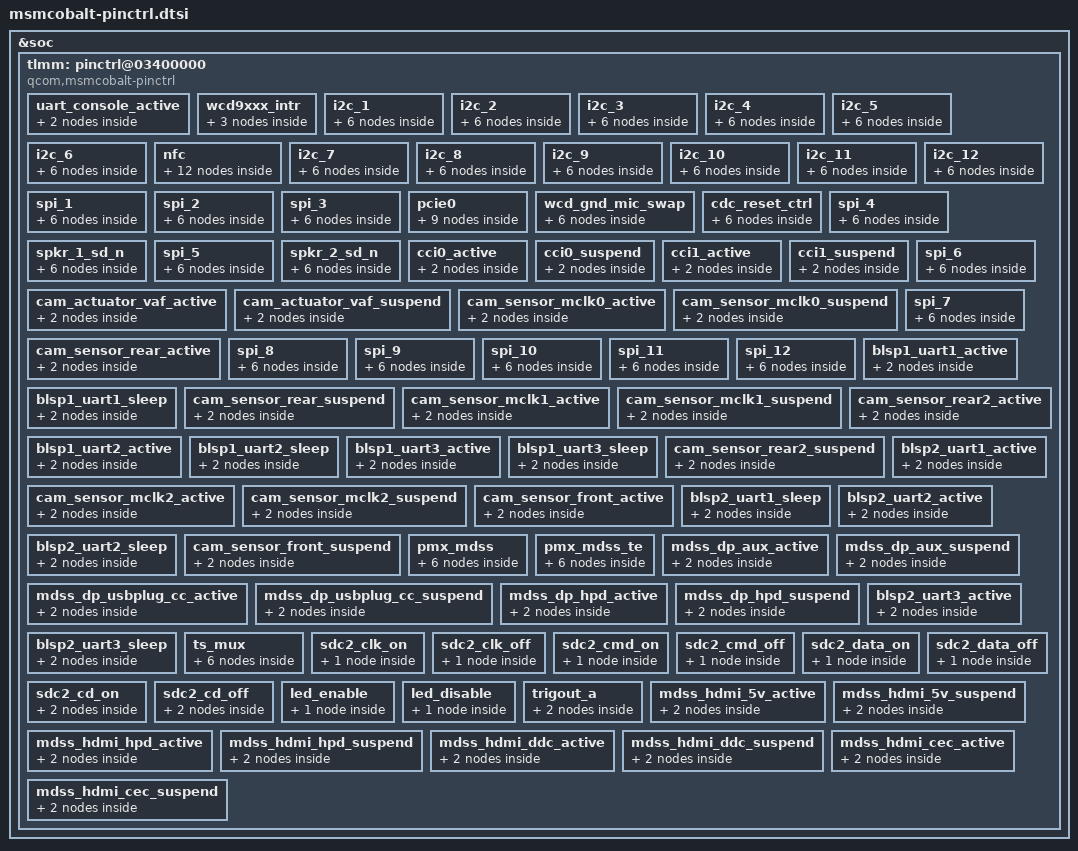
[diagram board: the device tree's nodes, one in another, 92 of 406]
/* Copyright (c) 2015-2016, The Linux Foundation. All rights reserved.
 *
 * This program is free software; you can redistribute it and/or modify
 * it under the terms of the GNU General Public License version 2 and
 * only version 2 as published by the Free Software Foundation.
 *
 * This program is distributed in the hope that it will be useful,
 * but WITHOUT ANY WARRANTY; without even the implied warranty of
 * MERCHANTABILITY or FITNESS FOR A PARTICULAR PURPOSE.  See the
 * GNU General Public License for more details.
 */

&soc {
	tlmm: pinctrl@03400000 {
		compatible = "qcom,msmcobalt-pinctrl";
		reg = <0x03400000 0xc00000>;
		interrupts = <0 208 0>;
		gpio-controller;
		#gpio-cells = <2>;
		interrupt-controller;
		#interrupt-cells = <2>;

		uart_console_active: uart_console_active {
			mux {
				pins = "gpio4", "gpio5";
				function = "blsp_uart8_a";
			};

			config {
				pins = "gpio4", "gpio5";
				drive-strength = <2>;
				bias-disable;
			};
		};

		wcd9xxx_intr {
			wcd_intr_default: wcd_intr_default{
				mux {
					pins = "gpio54";
					function = "gpio";
				};

				config {
					pins = "gpio54";
					drive-strength = <2>; /* 2 mA */
					bias-pull-down; /* pull down */
					input-enable;
				};
			};
		};

		/* I2C CONFIGURATION */
		i2c_1 {
			i2c_1_active: i2c_1_active {
				mux {
					pins = "gpio2", "gpio3";
					function = "blsp_i2c1";
				};

				config {
					pins = "gpio2", "gpio3";
					drive-strength = <2>;
					bias-disable;
				};
			};

			i2c_1_sleep: i2c_1_sleep {
				mux {
					pins = "gpio2", "gpio3";
					function = "blsp_i2c1";
				};

				config {
					pins = "gpio2", "gpio3";
					drive-strength = <2>;
					bias-pull-up;
				};
			};
		};

		i2c_2 {
			i2c_2_active: i2c_2_active {
				mux {
					pins = "gpio32", "gpio33";
					function = "blsp_i2c2";
				};

				config {
					pins = "gpio32", "gpio33";
					drive-strength = <2>;
					bias-disable;
				};
			};

			i2c_2_sleep: i2c_2_sleep {
				mux {
					pins = "gpio32", "gpio33";
					function = "blsp_i2c2";
				};

				config {
					pins = "gpio32", "gpio33";
					drive-strength = <2>;
					bias-pull-up;
				};
			};
		};

		i2c_3 {
			i2c_3_active: i2c_3_active {
				mux {
					pins = "gpio47", "gpio48";
					function = "blsp_i2c3";
				};

				config {
					pins = "gpio47", "gpio48";
					drive-strength = <2>;
					bias-disable;
				};
			};

			i2c_3_sleep: i2c_3_sleep {
				mux {
					pins = "gpio47", "gpio48";
					function = "blsp_i2c3";
				};

				config {
					pins = "gpio47", "gpio48";
					drive-strength = <2>;
					bias-pull-up;
				};
			};
		};

		i2c_4 {
			i2c_4_active: i2c_4_active {
				mux {
					pins = "gpio10", "gpio11";
					function = "blsp_i2c4";
				};

				config {
					pins = "gpio10", "gpio11";
					drive-strength = <2>;
					bias-disable;
				};
			};

			i2c_4_sleep: i2c_4_sleep {
				mux {
					pins = "gpio10", "gpio11";
					function = "blsp_i2c4";
				};

				config {
					pins = "gpio10", "gpio11";
					drive-strength = <2>;
					bias-pull-up;
				};
			};
		};

		i2c_5 {
			i2c_5_active: i2c_5_active {
				mux {
					pins = "gpio87", "gpio88";
					function = "blsp_i2c5";
				};

				config {
					pins = "gpio87", "gpio88";
					drive-strength = <2>;
					bias-disable;
				};
			};

			i2c_5_sleep: i2c_5_sleep {
				mux {
					pins = "gpio87", "gpio88";
					function = "blsp_i2c5";
				};

				config {
					pins = "gpio87", "gpio88";
					drive-strength = <2>;
					bias-pull-up;
				};
			};
		};

		i2c_6 {
			i2c_6_active: i2c_6_active {
				mux {
					pins = "gpio43", "gpio44";
					function = "blsp_i2c6";
				};

				config {
					pins = "gpio43", "gpio44";
					drive-strength = <2>;
					bias-disable;
				};
			};

			i2c_6_sleep: i2c_6_sleep {
				mux {
					pins = "gpio43", "gpio44";
					function = "blsp_i2c6";
				};

				config {
					pins = "gpio43", "gpio44";
					drive-strength = <2>;
					bias-pull-up;
				};
			};
		};

		nfc {
			nfc_int_active: nfc_int_active {
				/* active state */
				mux {
					/* GPIO 92 NFC Read Interrupt */
					pins = "gpio92";
					function = "gpio";
				};

				config {
					pins = "gpio92";
					drive-strength = <6>; /* 6 MA */
					bias-pull-up;
				};
			};

			nfc_int_suspend: nfc_int_suspend {
				/* sleep state */
				mux {
					/* GPIO 92 NFC Read Interrupt */
					pins = "gpio92";
					function = "gpio";
				};

				config {
					pins = "gpio92";
					drive-strength = <6>; /* 6 MA */
					bias-pull-up;
				};
			};

			nfc_enable_active: nfc_enable_active {
				/* active state */
				mux {
					/* 12: NFC ENABLE 116:ESE Enable */
					pins = "gpio12", "gpio116";
					function = "gpio";
				};

				config {
					pins = "gpio12", "gpio116";
					drive-strength = <6>; /* 6 MA */
					bias-pull-up;
				};
			};

			nfc_enable_suspend: nfc_enable_suspend {
				/* sleep state */
				mux {
					/* 12: NFC ENABLE 116:ESE Enable */
					pins = "gpio12", "gpio116";
					function = "gpio";
				};

				config {
					pins = "gpio12", "gpio116";
					drive-strength = <6>; /* 6 MA */
					bias-disable;
				};
			};
		};

		i2c_7 {
			i2c_7_active: i2c_7_active {
				mux {
					pins = "gpio55", "gpio56";
					function = "blsp_i2c7";
				};

				config {
					pins = "gpio55", "gpio56";
					drive-strength = <2>;
					bias-disable;
				};
			};

			i2c_7_sleep: i2c_7_sleep {
				mux {
					pins = "gpio55", "gpio56";
					function = "blsp_i2c7";
				};

				config {
					pins = "gpio55", "gpio56";
					drive-strength = <2>;
					bias-pull-up;
				};
			};
		};

		i2c_8 {
			i2c_8_active: i2c_8_active {
				mux {
					pins = "gpio6", "gpio7";
					function = "blsp_i2c8";
				};

				config {
					pins = "gpio6", "gpio7";
					drive-strength = <2>;
					bias-disable;
				};
			};

			i2c_8_sleep: i2c_8_sleep {
				mux {
					pins = "gpio6", "gpio7";
					function = "blsp_i2c8";
				};

				config {
					pins = "gpio6", "gpio7";
					drive-strength = <2>;
					bias-pull-up;
				};
			};
		};

		i2c_9 {
			i2c_9_active: i2c_9_active {
				mux {
					pins = "gpio51", "gpio52";
					function = "blsp_i2c9";
				};

				config {
					pins = "gpio51", "gpio52";
					drive-strength = <2>;
					bias-disable;
				};
			};

			i2c_9_sleep: i2c_9_sleep {
				mux {
					pins = "gpio51", "gpio52";
					function = "blsp_i2c9";
				};

				config {
					pins = "gpio51", "gpio52";
					drive-strength = <2>;
					bias-pull-up;
				};
			};
		};

		i2c_10 {
			i2c_10_active: i2c_10_active {
				mux {
					pins = "gpio67", "gpio68";
					function = "blsp_i2c10";
				};

				config {
					pins = "gpio67", "gpio68";
					drive-strength = <2>;
					bias-disable;
				};
			};

			i2c_10_sleep: i2c_10_sleep {
				mux {
					pins = "gpio67", "gpio68";
					function = "blsp_i2c10";
				};

				config {
					pins = "gpio67", "gpio68";
					drive-strength = <2>;
					bias-pull-up;
				};
			};
		};

		i2c_11 {
			i2c_11_active: i2c_11_active {
				mux {
					pins = "gpio60", "gpio61";
					function = "blsp_i2c11";
				};

				config {
					pins = "gpio60", "gpio61";
					drive-strength = <2>;
					bias-disable;
				};
			};

			i2c_11_sleep: i2c_11_sleep {
				mux {
					pins = "gpio60", "gpio61";
					function = "blsp_i2c11";
				};

				config {
					pins = "gpio60", "gpio61";
					drive-strength = <2>;
					bias-pull-up;
				};
			};
		};

		i2c_12 {
			i2c_12_active: i2c_12_active {
				mux {
					pins = "gpio83", "gpio84";
					function = "blsp_i2c12";
				};

				config {
					pins = "gpio83", "gpio84";
					drive-strength = <2>;
					bias-disable;
				};
			};

			i2c_12_sleep: i2c_12_sleep {
				mux {
					pins = "gpio83", "gpio84";
					function = "blsp_i2c12";
				};

				config {
					pins = "gpio83", "gpio84";
					drive-strength = <2>;
					bias-pull-up;
				};
			};
		};

		/* SPI CONFIGURATION */

		spi_1 {
			spi_1_active: spi_1_active {
				mux {
					pins = "gpio0", "gpio1",
							"gpio2", "gpio3";
					function = "blsp_spi1";
				};

				config {
					pins = "gpio0", "gpio1",
							"gpio2", "gpio3";
					drive-strength = <6>;
					bias-disable;
				};
			};

			spi_1_sleep: spi_1_sleep {
				mux {
					pins = "gpio0", "gpio1",
							"gpio2", "gpio3";
					function = "blsp_spi1";
				};

				config {
					pins = "gpio0", "gpio1",
							"gpio2", "gpio3";
					drive-strength = <6>;
					bias-disable;
				};
			};
		};

		spi_2 {
			spi_2_active: spi_2_active {
				mux {
					pins = "gpio31", "gpio34",
							"gpio32", "gpio33";
					function = "blsp_spi2";
				};

				config {
					pins = "gpio31", "gpio34",
							"gpio32", "gpio33";
					drive-strength = <6>;
					bias-disable;
				};
			};

			spi_2_sleep: spi_2_sleep {
				mux {
					pins = "gpio31", "gpio34",
							"gpio32", "gpio33";
					function = "blsp_spi2";
				};

				config {
					pins = "gpio31", "gpio34",
							"gpio32", "gpio33";
					drive-strength = <6>;
					bias-disable;
				};
			};
		};

		spi_3 {
			spi_3_active: spi_3_active {
				mux {
					pins = "gpio45", "gpio46",
							"gpio47", "gpio48";
					function = "blsp_spi3";
				};

				config {
					pins = "gpio45", "gpio46",
							"gpio47", "gpio48";
					drive-strength = <6>;
					bias-disable;
				};
			};

			spi_3_sleep: spi_3_sleep {
				mux {
					pins = "gpio45", "gpio46",
							"gpio47", "gpio48";
					function = "blsp_spi3";
				};

				config {
					pins = "gpio45", "gpio46",
							"gpio47", "gpio48";
					drive-strength = <6>;
					bias-disable;
				};
			};
		};

		pcie0 {
			pcie0_clkreq_default: pcie0_clkreq_default {
				mux {
					pins = "gpio36";
					function = "pci_e0";
				};

				config {
					pins = "gpio36";
					drive-strength = <2>;
					bias-pull-up;
				};
			};

			pcie0_perst_default: pcie0_perst_default {
				mux {
					pins = "gpio35";
					function = "gpio";
				};

				config {
					pins = "gpio35";
					drive-strength = <2>;
					bias-pull-down;
				};
			};

			pcie0_wake_default: pcie0_wake_default {
				mux {
					pins = "gpio37";
					function = "gpio";
				};

				config {
					pins = "gpio37";
					drive-strength = <2>;
					bias-pull-down;
				};
			};
		};

		wcd_gnd_mic_swap {
			wcd_gnd_mic_swap_idle: wcd_gnd_mic_swap_idle {
				mux {
					pins = "gpio75";
					function = "gpio";
				};
				config {
					pins = "gpio75";
					drive-strength = <2>;
					bias-pull-down;
					output-low;
				};
			};
			wcd_gnd_mic_swap_active: wcd_gnd_mic_swap_active {
				mux {
					pins = "gpio75";
					function = "gpio";
				};
				config {
					pins = "gpio75";
					drive-strength = <2>;
					bias-disable;
					output-high;
				};
			};
		};


		cdc_reset_ctrl {
			cdc_reset_sleep: cdc_reset_sleep {
				mux {
					pins = "gpio64";
					function = "gpio";
				};
				config {
					pins = "gpio64";
					drive-strength = <16>;
					bias-disable;
					output-low;
				};
			};
			cdc_reset_active:cdc_reset_active {
				mux {
					pins = "gpio64";
					function = "gpio";
				};
				config {
					pins = "gpio64";
					drive-strength = <16>;
					bias-pull-down;
					output-high;
				};
			};
		};

		spi_4 {
			spi_4_active: spi_4_active {
				mux {
					pins = "gpio8", "gpio9",
							"gpio10", "gpio1";
					function = "blsp_spi4";
				};

				config {
					pins = "gpio8", "gpio9",
							"gpio10", "gpio1";
					drive-strength = <6>;
					bias-disable;
				};
			};

			spi_4_sleep: spi_4_sleep {
				mux {
					pins = "gpio8", "gpio9",
							"gpio10", "gpio1";
					function = "blsp_spi4";
				};

				config {
					pins = "gpio8", "gpio9",
							"gpio10", "gpio1";
					drive-strength = <6>;
					bias-disable;
				};
			};
		};

		spkr_1_sd_n {
			spkr_1_sd_n_sleep: spkr_1_sd_n_sleep {
				mux {
					pins = "gpio65";
					function = "gpio";
				};
				config {
					pins = "gpio65";
					drive-strength = <2>;   /* 2 mA */
					bias-pull-down;
					input-enable;
				};
			};
			spkr_1_sd_n_active: spkr_1_sd_n_active {
				mux {
					pins = "gpio65";
					function = "gpio";
				};
				config {
					pins = "gpio65";
					drive-strength = <16>;   /* 16 mA */
					bias-disable;
					output-high;
				};
			};
		};

		spi_5 {
			spi_5_active: spi_5_active {
				mux {
					pins = "gpio0", "gpio",
							"gpio2", "gpio3";
					function = "blsp_spi5";
				};

				config {
					pins = "gpio85", "gpio86",
							"gpio87", "gpio88";
					drive-strength = <6>;
					bias-disable;
				};
			};

			spi_5_sleep: spi_5_sleep {
				mux {
					pins = "gpio85", "gpio86",
							"gpio87", "gpio88";
					function = "blsp_spi5";
				};

				config {
					pins = "gpio85", "gpio86",
							"gpio87", "gpio88";
					drive-strength = <6>;
					bias-disable;
				};
			};
		};

		spkr_2_sd_n {
			spkr_2_sd_n_sleep: spkr_2_sd_n_sleep {
				mux {
					pins = "gpio66";
					function = "gpio";
				};
				config {
					pins = "gpio66";
					drive-strength = <2>;   /* 2 mA */
					bias-pull-down;
					input-enable;
				};
			};
			spkr_2_sd_n_active: spkr_2_sd_n_active {
				mux {
					pins = "gpio66";
					function = "gpio";
				};
				config {
					pins = "gpio66";
					drive-strength = <16>;   /* 16 mA */
					bias-disable;
					output-high;
				};
			};
		};

		cci0_active: cci0_active {
			mux {
				/* CLK, DATA */
				pins = "gpio17","gpio18"; // Only 2
				function = "cci_i2c";
			};

			config {
				pins = "gpio17","gpio18";
				bias-pull-up; /* PULL UP*/
				drive-strength = <2>; /* 2 MA */
			};
		};

		cci0_suspend: cci0_suspend {
			mux {
				/* CLK, DATA */
				pins = "gpio17","gpio18";
				function = "cci_i2c";
			};

			config {
				pins = "gpio17","gpio18";
				bias-pull-down; /* PULL DOWN */
				drive-strength = <2>; /* 2 MA */
			};
		};

		cci1_active: cci1_active {
			mux {
				/* CLK, DATA */
				pins = "gpio19","gpio20";
				function = "cci_i2c";
			};

			config {
				pins = "gpio19","gpio20";
				bias-pull-up; /* PULL UP*/
				drive-strength = <2>; /* 2 MA */
			};
		};

		cci1_suspend: cci1_suspend {
			mux {
				/* CLK, DATA */
				pins = "gpio19","gpio20";
				function = "cci_i2c";
			};

			config {
				pins = "gpio19","gpio20";
				bias-pull-down; /* PULL DOWN */
				drive-strength = <2>; /* 2 MA */
			};
		};

		cam_actuator_vaf_active: cam_actuator_vaf_active {
			/* ACTUATOR POWER */
			mux {
				pins = "gpio27";
				function = "gpio";
			};

			config {
				pins = "gpio27";
				bias-disable; /* No PULL */
				drive-strength = <2>; /* 2 MA */
			};
		};

		cam_actuator_vaf_suspend: cam_actuator_vaf_suspend {
			/* ACTUATOR POWER */
			mux {
				pins = "gpio27";
				function = "gpio";
			};

			config {
				pins = "gpio27";
				bias-pull-down; /* PULL DOWN */
				drive-strength = <2>; /* 2 MA */
			};
		};

		cam_sensor_mclk0_active: cam_sensor_mclk0_active {
			/* MCLK0 */
			mux {
				/* CLK, DATA */
				pins = "gpio13";
				function = "cam_mclk";
			};

			config {
				pins = "gpio13";
				bias-disable; /* No PULL */
				drive-strength = <2>; /* 2 MA */
			};
		};

		cam_sensor_mclk0_suspend: cam_sensor_mclk0_suspend {
			/* MCLK0 */
			mux {
				/* CLK, DATA */
				pins = "gpio13";
				function = "cam_mclk";
			};

			config {
				pins = "gpio13";
				bias-pull-down; /* PULL DOWN */
				drive-strength = <2>; /* 2 MA */
			};
		};

		cam_sensor_rear_active: cam_sensor_rear_active {
			/* RESET, STANDBY */
			mux {
				pins = "gpio30","gpio29";
				function = "gpio";
			};

			config {
				pins = "gpio30","gpio29";
				bias-disable; /* No PULL */
				drive-strength = <2>; /* 2 MA */
			};
		};

		spi_6 {
			spi_6_active: spi_6_active {
				mux {
					pins = "gpio41", "gpio42",
							"gpio43", "gpio44";
					function = "blsp_spi6";
				};

				config {
					pins = "gpio41", "gpio42",
							"gpio43", "gpio44";
					drive-strength = <6>;
					bias-disable;
				};
			};

			spi_6_sleep: spi_6_sleep {
				mux {
					pins = "gpio41", "gpio42",
							"gpio43", "gpio44";
					function = "blsp_spi6";
				};

				config {
					pins = "gpio41", "gpio42",
							"gpio43", "gpio44";
					drive-strength = <6>;
					bias-disable;
				};
			};
		};

		spi_7 {
			spi_7_active: spi_7_active {
				mux {
					pins = "gpio53", "gpio54",
							"gpio55", "gpio56";
					function = "blsp_spi7";
				};

				config {
					pins = "gpio53", "gpio54",
							"gpio55", "gpio56";
					drive-strength = <6>;
					bias-disable;
				};
			};

			spi_7_sleep: spi_7_sleep {
				mux {
					pins = "gpio53", "gpio54",
							"gpio55", "gpio56";
					function = "blsp_spi7";
				};

				config {
					pins = "gpio53", "gpio54",
							"gpio55", "gpio56";
					drive-strength = <6>;
					bias-disable;
				};
			};
		};

		spi_8 {
			spi_8_active: spi_8_active {
				mux {
					pins = "gpio4", "gpio5",
							"gpio6", "gpio7";
					function = "blsp_spi8";
				};

				config {
					pins = "gpio4", "gpio5",
							"gpio6", "gpio7";
					drive-strength = <6>;
					bias-disable;
				};
			};

			spi_8_sleep: spi_8_sleep {
				mux {
					pins = "gpio4", "gpio5",
							"gpio6", "gpio7";
					function = "blsp_spi8";
				};

				config {
					pins = "gpio4", "gpio5",
							"gpio6", "gpio7";
					drive-strength = <6>;
					bias-disable;
				};
			};
		};

		spi_9 {
			spi_9_active: spi_9_active {
				mux {
					pins = "gpio49", "gpio50",
							"gpio51", "gpio52";
					function = "blsp_spi9";
				};

				config {
					pins = "gpio49", "gpio50",
							"gpio51", "gpio52";
					drive-strength = <6>;
					bias-disable;
				};
			};

			spi_9_sleep: spi_9_sleep {
				mux {
					pins = "gpio49", "gpio50",
							"gpio51", "gpio52";
					function = "blsp_spi9";
				};

				config {
					pins = "gpio49", "gpio50",
							"gpio51", "gpio52";
					drive-strength = <6>;
					bias-disable;
				};
			};
		};

		spi_10 {
			spi_10_active: spi_10_active {
				mux {
					pins = "gpio65", "gpio66",
							"gpio67", "gpio68";
					function = "blsp_spi10";
				};

				config {
					pins = "gpio65", "gpio66",
							"gpio67", "gpio68";
					drive-strength = <6>;
					bias-disable;
				};
			};

			spi_10_sleep: spi_10_sleep {
				mux {
					pins = "gpio65", "gpio66",
							"gpio67", "gpio68";
					function = "blsp_spi10";
				};

				config {
					pins = "gpio65", "gpio66",
							"gpio67", "gpio68";
					drive-strength = <6>;
					bias-disable;
				};
			};
		};

		spi_11 {
			spi_11_active: spi_11_active {
				mux {
					pins = "gpio58", "gpio59",
							"gpio60", "gpio61";
					function = "blsp_spi11";
				};

				config {
					pins = "gpio58", "gpio59",
							"gpio60", "gpio61";
					drive-strength = <6>;
					bias-disable;
				};
			};

			spi_11_sleep: spi_11_sleep {
				mux {
					pins = "gpio58", "gpio59",
							"gpio60", "gpio61";
					function = "blsp_spi11";
				};

				config {
					pins = "gpio58", "gpio59",
							"gpio60", "gpio61";
					drive-strength = <6>;
					bias-disable;
				};
			};
		};

		spi_12 {
			spi_12_active: spi_12_active {
				mux {
					pins = "gpio81", "gpio82",
							"gpio83", "gpio84";
					function = "blsp_spi12";
				};

				config {
					pins = "gpio81", "gpio82",
							"gpio83", "gpio84";
					drive-strength = <6>;
					bias-disable;
				};
			};

			spi_12_sleep: spi_12_sleep {
				mux {
					pins = "gpio81", "gpio82",
							"gpio83", "gpio84";
					function = "blsp_spi12";
				};

				config {
					pins = "gpio81", "gpio82",
							"gpio83", "gpio84";
					drive-strength = <6>;
					bias-disable;
				};
			};
		};

		/* HS UART CONFIGURATION */
		blsp1_uart1_active: blsp1_uart1_active {
			mux {
				pins = "gpio0", "gpio1", "gpio2", "gpio3";
				function = "blsp_uart1_a";
			};

			config {
				pins = "gpio0", "gpio1", "gpio2", "gpio3";
				drive-strength = <2>;
				bias-disable;
			};
		};

		blsp1_uart1_sleep: blsp1_uart1_sleep {
			mux {
				pins = "gpio0", "gpio1", "gpio2", "gpio3";
				function = "gpio";
			};

			config {
				pins = "gpio0", "gpio1", "gpio2", "gpio3";
				drive-strength = <2>;
				bias-disable;
			};
		};

		cam_sensor_rear_suspend: cam_sensor_rear_suspend {
			/* RESET, STANDBY */
			mux {
				pins = "gpio30","gpio29";
				function = "gpio";
			};

			config {
				pins = "gpio30","gpio29";
				bias-disable; /* No PULL */
				drive-strength = <2>; /* 2 MA */
			};
		};

		cam_sensor_mclk1_active: cam_sensor_mclk1_active {
			/* MCLK1 */
			mux {
				/* CLK, DATA */
				pins = "gpio14";
				function = "cam_mclk";
			};

			config {
				pins = "gpio14";
				bias-disable; /* No PULL */
				drive-strength = <2>; /* 2 MA */
			};
		};

		cam_sensor_mclk1_suspend: cam_sensor_mclk1_suspend {
			/* MCLK1 */
			mux {
				/* CLK, DATA */
				pins = "gpio14";
				function = "cam_mclk";
			};

			config {
				pins = "gpio14";
				bias-pull-down; /* PULL DOWN */
				drive-strength = <2>; /* 2 MA */
			};
		};

		cam_sensor_rear2_active: cam_sensor_rear2_active {
			/* RESET, STANDBY */
			mux {
				pins = "gpio9","gpio8";
				function = "gpio";
			};

			config {
				pins = "gpio9","gpio8";
				bias-disable; /* No PULL */
				drive-strength = <2>; /* 2 MA */
			};
		};

		blsp1_uart2_active: blsp1_uart2_active {
			mux {
				pins = "gpio31", "gpio34", "gpio33", "gpio32";
				function = "blsp_uart2_a";
			};

			config {
				pins = "gpio31", "gpio34", "gpio33", "gpio32";
				drive-strength = <2>;
				bias-disable;
			};
		};

		blsp1_uart2_sleep: blsp1_uart2_sleep {
			mux {
				pins = "gpio31", "gpio34", "gpio33", "gpio32";
				function = "gpio";
			};

			config {
				pins = "gpio31", "gpio34", "gpio33", "gpio32";
				drive-strength = <2>;
				bias-disable;
			};
		};

		blsp1_uart3_active: blsp1_uart3_active {
			mux {
				pins = "gpio45", "gpio46", "gpio47", "gpio48";
				function = "blsp_uart3_a";
			};

			config {
				pins = "gpio45", "gpio46", "gpio47", "gpio48";
				drive-strength = <2>;
				bias-disable;
			};
		};

		blsp1_uart3_sleep: blsp1_uart3_sleep {
			mux {
				pins = "gpio45", "gpio46", "gpio47", "gpio48";
				function = "gpio";
			};

			config {
				pins = "gpio45", "gpio46", "gpio47", "gpio48";
				drive-strength = <2>;
				bias-disable;
			};
		};

		cam_sensor_rear2_suspend: cam_sensor_rear2_suspend {
			/* RESET, STANDBY */
			mux {
				pins = "gpio9","gpio8";
				function = "gpio";
			};
			config {
				pins = "gpio9","gpio8";
				bias-disable; /* No PULL */
				drive-strength = <2>; /* 2 MA */
			};
		};

		cam_sensor_mclk2_active: cam_sensor_mclk2_active {
			/* MCLK1 */
			mux {
				/* CLK, DATA */
				pins = "gpio15";
				function = "cam_mclk";
			};

			config {
				pins = "gpio15";
				bias-disable; /* No PULL */
				drive-strength = <2>; /* 2 MA */
			};
		};

		cam_sensor_mclk2_suspend: cam_sensor_mclk2_suspend {
			/* MCLK1 */
			mux {
				/* CLK, DATA */
				pins = "gpio15";
				function = "cam_mclk";
			};

			config {
				pins = "gpio15";
				bias-pull-down; /* PULL DOWN */
				drive-strength = <2>; /* 2 MA */
			};
		};

		cam_sensor_front_active: cam_sensor_front_active {
			/* RESET */
			mux {
				pins = "gpio28";
				function = "gpio";
			};

			config {
				pins = "gpio28";
				bias-disable; /* No PULL */
				drive-strength = <2>; /* 2 MA */
			};
		};

		blsp2_uart1_active: blsp2_uart1_active {
			mux {
				pins = "gpio53", "gpio54", "gpio55", "gpio56";
				function = "blsp_uart7_a";
			};

			config {
				pins = "gpio53", "gpio54", "gpio55", "gpio56";
				drive-strength = <2>;
				bias-disable;
			};
		};

		blsp2_uart1_sleep: blsp2_uart1_sleep {
			mux {
				pins = "gpio53", "gpio54", "gpio55", "gpio56";
				function = "gpio";
			};

			config {
				pins = "gpio53", "gpio54", "gpio55", "gpio56";
				drive-strength = <2>;
				bias-disable;
			};
		};

		blsp2_uart2_active: blsp2_uart2_active {
			mux {
				pins = "gpio4", "gpio5", "gpio6", "gpio7";
				function = "blsp_uart8_a";
			};

			config {
				pins = "gpio4", "gpio5", "gpio6", "gpio7";
				drive-strength = <2>;
				bias-disable;
			};
		};

		blsp2_uart2_sleep: blsp2_uart2_sleep {
			mux {
				pins = "gpio4", "gpio5", "gpio6", "gpio7";
				function = "gpio";
			};

			config {
				pins = "gpio4", "gpio5", "gpio6", "gpio7";
				drive-strength = <2>;
				bias-disable;
			};
		};

		cam_sensor_front_suspend: cam_sensor_front_suspend {
			/* RESET */
			mux {
				pins = "gpio28";
				function = "gpio";
			};

			config {
				pins = "gpio28";
				bias-disable; /* No PULL */
				drive-strength = <2>; /* 2 MA */
			};
		};

		pmx_mdss: pmx_mdss {
			mdss_dsi_active: mdss_dsi_active {
				mux {
					pins = "gpio94", "gpio91", "gpio51";
					function = "gpio";
				};

				config {
					pins = "gpio94", "gpio91", "gpio51";
					drive-strength = <8>; /* 8 mA */
					bias-disable = <0>; /* no pull */
				};
			};
			mdss_dsi_suspend: mdss_dsi_suspend {
				mux {
					pins = "gpio94", "gpio91", "gpio51";
					function = "gpio";
				};

				config {
					pins = "gpio94", "gpio91", "gpio51";
					drive-strength = <2>; /* 2 mA */
					bias-pull-down; /* pull down */
				};
			};
		};

		pmx_mdss_te {
			mdss_te_active: mdss_te_active {
				mux {
					pins = "gpio10";
					function = "mdp_vsync_a";
				};
				config {
					pins = "gpio10";
					drive-strength = <2>; /* 8 mA */
					bias-pull-down; /* pull down*/
				};
			};

			mdss_te_suspend: mdss_te_suspend {
				mux {
					pins = "gpio10";
					function = "mdp_vsync_a";
				};
				config {
					pins = "gpio10";
					drive-strength = <2>; /* 2 mA */
					bias-pull-down; /* pull down */
				};
			};
		};

		mdss_dp_aux_active: mdss_dp_aux_active {
			mux {
				pins = "gpio77", "gpio78";
				function = "gpio";
			};

			config {
				pins = "gpio77", "gpio78";
				bias-disable = <0>; /* no pull */
				drive-strength = <8>;
			};
		};

		mdss_dp_aux_suspend: mdss_dp_aux_suspend {
			mux {
				pins = "gpio77", "gpio78";
				function = "gpio";
			};

			config {
				pins = "gpio77", "gpio78";
				bias-pull-down;
				drive-strength = <2>;
			};
		};

		mdss_dp_usbplug_cc_active: mdss_dp_usbplug_cc_active {
			mux {
				pins = "gpio38";
				function = "usb_phy";
			};

			config {
				pins = "gpio38";
				bias-disable;
				drive-strength = <16>;
			};
		};

		mdss_dp_usbplug_cc_suspend: mdss_dp_usbplug_cc_suspend {
			mux {
				pins = "gpio38";
				function = "usb_phy";
			};

			config {
				pins = "gpio38";
				bias-pull-down;
				drive-strength = <2>;
			};
		};

		mdss_dp_hpd_active: mdss_dp_hpd_active {
			mux {
				pins = "gpio34";
				function = "edp_hot";
			};

			config {
				pins = "gpio34";
				bias-pull-down;
				drive-strength = <16>;
			};
		};

		mdss_dp_hpd_suspend: mdss_dp_hpd_suspend {
			mux {
				pins = "gpio34";
				function = "edp_hot";
			};

			config {
				pins = "gpio34";
				bias-pull-down;
				drive-strength = <2>;
			};
		};

		blsp2_uart3_active: blsp2_uart3_active {
			mux {
				pins = "gpio49", "gpio50", "gpio51", "gpio52";
				function = "blsp_uart9_a";
			};

			config {
				pins = "gpio49", "gpio50", "gpio51", "gpio52";
				drive-strength = <2>;
				bias-disable;
			};
		};

		blsp2_uart3_sleep: blsp2_uart3_sleep {
			mux {
				pins = "gpio49", "gpio50", "gpio51", "gpio52";
				function = "gpio";
			};

			config {
				pins = "gpio49", "gpio50", "gpio51", "gpio52";
				drive-strength = <2>;
				bias-disable;
			};
		};

		ts_mux {
			ts_active: ts_active {
				mux {
					pins = "gpio89", "gpio125";
					function = "gpio";
				};

				config {
					pins = "gpio89", "gpio125";
					drive-strength = <16>;
					bias-pull-up;
				};
			};

			ts_suspend: ts_suspend {
				mux {
					pins = "gpio89", "gpio125";
					function = "gpio";
				};

				config {
					pins = "gpio89", "gpio125";
					drive-strength = <2>;
					bias-pull-down;
				};
			};
		};

		sdc2_clk_on: sdc2_clk_on {
			config {
				pins = "sdc2_clk";
				bias-disable;		/* NO pull */
				drive-strength = <16>;	/* 16 MA */
			};
		};

		sdc2_clk_off: sdc2_clk_off {
			config {
				pins = "sdc2_clk";
				bias-disable;		/* NO pull */
				drive-strength = <2>;	/* 2 MA */
			};
		};

		sdc2_cmd_on: sdc2_cmd_on {
			config {
				pins = "sdc2_cmd";
				bias-pull-up;		/* pull up */
				drive-strength = <10>;	/* 10 MA */
			};
		};

		sdc2_cmd_off: sdc2_cmd_off {
			config {
				pins = "sdc2_cmd";
				bias-pull-up;		/* pull up */
				drive-strength = <2>;	/* 2 MA */
			};
		};

		sdc2_data_on: sdc2_data_on {
			config {
				pins = "sdc2_data";
				bias-pull-up;		/* pull up */
				drive-strength = <10>;	/* 10 MA */
			};
		};

		sdc2_data_off: sdc2_data_off {
			config {
				pins = "sdc2_data";
				bias-pull-up;		/* pull up */
				drive-strength = <2>;	/* 2 MA */
			};
		};

		sdc2_cd_on: sdc2_cd_on {
			mux {
				pins = "gpio95";
				function = "gpio";
			};

			config {
				pins = "gpio95";
				bias-pull-up;           /* pull up */
				drive-strength = <2>;   /* 2 MA */
			};
		};

		sdc2_cd_off: sdc2_cd_off {
			mux {
				pins = "gpio95";
				function = "gpio";
			};

			config {
				pins = "gpio95";
				bias-pull-up;           /* pull up */
				drive-strength = <2>;   /* 2 MA */
			};

		};

		led_enable: led_enable {
			mux {
				pins = "gpio21";
				drive_strength = <16>;
				output-high;
			};
		};

		led_disable: led_disable {
			mux {
				pins = "gpio21";
				drive_strength = <2>;
				output-low;
			};
		};

		trigout_a: trigout_a {
			mux {
				pins = "gpio58";
				function = "qdss_cti1_a";
			};

			config {
				pins = "gpio58";
				drive-strength = <2>;
				bias-disable;
			};
		};

		mdss_hdmi_5v_active: mdss_hdmi_5v_active {
			mux {
				pins = "gpio133";
				function = "gpio";
			};

			config {
				pins = "gpio133";
				bias-pull-up;
				drive-strength = <16>;
			};
		};

		mdss_hdmi_5v_suspend: mdss_hdmi_5v_suspend {
			mux {
				pins = "gpio133";
				function = "gpio";
			};

			config {
				pins = "gpio133";
				bias-pull-down;
				drive-strength = <2>;
			};
		};


		mdss_hdmi_hpd_active: mdss_hdmi_hpd_active {
			mux {
				pins = "gpio34";
				function = "hdmi_hot";
			};

			config {
				pins = "gpio34";
				bias-pull-down;
				drive-strength = <16>;
			};
		};

		mdss_hdmi_hpd_suspend: mdss_hdmi_hpd_suspend {
			mux {
				pins = "gpio34";
				function = "hdmi_hot";
			};

			config {
				pins = "gpio34";
				bias-pull-down;
				drive-strength = <2>;
			};
		};

		mdss_hdmi_ddc_active: mdss_hdmi_ddc_active {
			mux {
				pins = "gpio32", "gpio33";
				function = "hdmi_ddc";
			};

			config {
				pins = "gpio32", "gpio33";
				drive-strength = <2>;
				bias-pull-up;
			};
		};

		mdss_hdmi_ddc_suspend: mdss_hdmi_ddc_suspend {
			mux {
				pins = "gpio32", "gpio33";
				function = "hdmi_ddc";
			};

			config {
				pins = "gpio32", "gpio33";
				drive-strength = <2>;
				bias-pull-up;
			};
		};

		mdss_hdmi_cec_active: mdss_hdmi_cec_active {
			mux {
				pins = "gpio31";
				function = "hdmi_cec";
			};

			config {
				pins = "gpio31";
				drive-strength = <2>;
				bias-pull-up;
			};
		};

		mdss_hdmi_cec_suspend: mdss_hdmi_cec_suspend {
			mux {
				pins = "gpio31";
				function = "hdmi_cec";
			};

			config {
				pins = "gpio31";
				drive-strength = <2>;
				bias-pull-up;
			};
		};
	};
};
